# LKS32MC03x register map
Vendor: Linko Ltd.; Series: LKS32MC03x; File version: 1.0
CPU: CM0 r1p0, little endian, MPU, no FPU, 3 interrupt priority bits
Registers are 32-bit, read-write, reset 0x0 unless marked. A register's access mark holds for its fields unless they carry their own. Offsets are from the block's base; [hi:lo] are bit positions; {n}, {i} and the like mark numbered series; 'fields as' and 'values as' point back to an identical list.

## EXTI — EXTI registers
Base 0x40010880
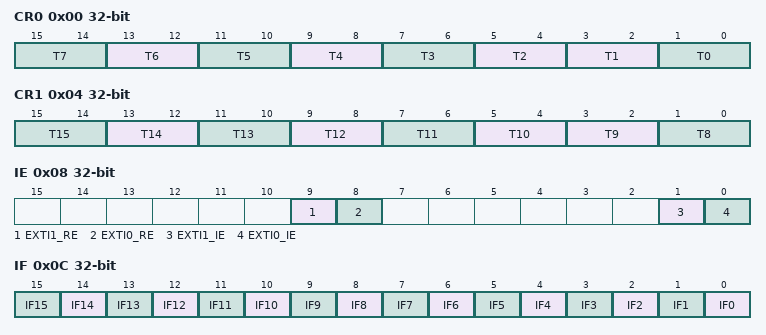
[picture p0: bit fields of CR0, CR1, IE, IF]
0x00 CR0 — GPIO0 external interrupt trigger type
  [all] fields
    0=NONE (No interrupt.); 1=FALLING (Interrupt on falling edge); 2=RISING (Interrupt on rising edge); 3=BOTH (Interrupt on both edges)
  [2n+1:2n] T{n} (n=2..7) — GPIO0[{n+2}] external interrupt trigger type
  [3:2] T1 — GPIO0[2] external interrupt trigger type
  [1:0] T0 — GPIO0[0] external interrupt trigger type
0x04 CR1 — GPIO external interrupt trigger type
  [all] fields
    values as the fields of CR0
  [2n-15:2n-16] T{n} (n=10..15) — GPIO1[{n-6}] external interrupt trigger type
  [3:2] T9 — GPIO0[15] external interrupt trigger type
  [1:0] T8 — GPIO0[14] external interrupt trigger type
0x08 IE — GPIO interrupt enable
  [9] EXTI1_RE — GPIO1 DMA enable
  [8] EXTI0_RE — GPIO0 DMA enable
  [1] EXTI1_IE — GPIO1 interrupt enable
  [0] EXTI0_IE — GPIO0 interrupt enable
0x0C IF — GPIO interrupt flag
  [n] IF{n} (n=0..15) — GPIO0[{n}] interrupt flag
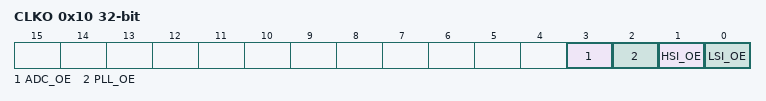
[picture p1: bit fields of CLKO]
0x10 CLKO — GPIO output clock selection
  [3] ADC_OE — ADC output enable
  [2] PLL_OE — PLL output enable
  [1] HSI_OE — HSI output enable
  [0] LSI_OE — LSI output enable

## UART — UART registers
Base 0x40010900
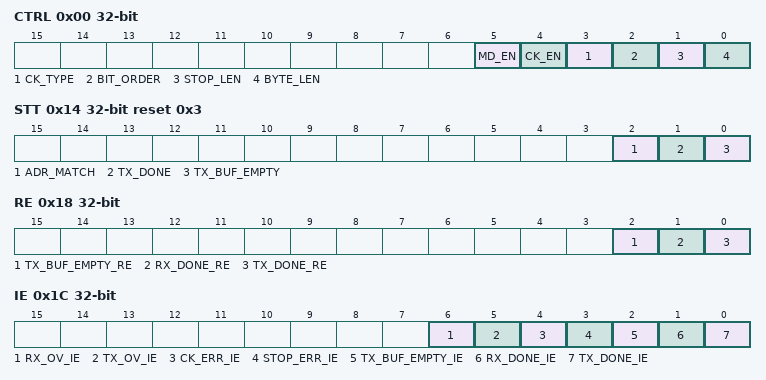
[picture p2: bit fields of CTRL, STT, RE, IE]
0x00 CTRL — UART control
  [5] MD_EN — Multi-drop mode enable
    0=DISABLED (Multi-drop mode disabled); 1=ENABLED (Multi-drop mode enabled)
  [4] CK_EN — Odd-Even Check enable
    0=DISABLED (Odd-Even check disabled); 1=ENABLED (Odd-Even check enabled)
  [3] CK_TYPE — Odd or Even Check
    0=EVEN (Even check); 1=ODD (Odd check)
  [2] BIT_ORDER — LSB or MSB first
    0=LSB; 1=MSB
  [1] STOP_LEN — Stop bit length
    0=1B (1bit stop bit); 1=2B (2bit stop bit)
  [0] BYTE_LEN — Data length
    0=8B (8bit data); 1=9B (9bit data)
0x04 DIVH — UART Baudrate higher byte
  [7:0] DIVH — Baudrate higher byte
0x08 DIVL — UART Baudrate lower byte
  [7:0] DIVL — Baudrate lower byte
0x0C BUFF — UART read/write buffer
  [8:0] DATA — Write by Tx data, read as Rx data
0x10 ADR — UART match address as RS485
  [7:0] ADR — UART address as a slave
0x14 STT ro reset 0x3 — UART status
  [2] ADR_MATCH — Address matched in multi-drop mode
  [1] TX_DONE — Transmission fnished
  [0] TX_BUF_EMPTY — TX Buffer empty
0x18 RE — UART DMA request enable
  [2] TX_BUF_EMPTY_RE — TX Buffer empty DMA request enable
  [1] RX_DONE_RE — Byte received DMA request enable
  [0] TX_DONE_RE — Byte transmission finished DMA request flag
0x1C IE — UART interrupt enable
  [6] RX_OV_IE — RX overflow interrupt enable
  [5] TX_OV_IE — TX overflow interrupt enable
  [4] CK_ERR_IE — Check error interrupt enable
  [3] STOP_ERR_IE — Stop bit error interrupt enable
  [2] TX_BUF_EMPTY_IE — TX Buffer empty interrupt enable
  [1] RX_DONE_IE — Byte received interrupt enable
  [0] TX_DONE_IE — Byte transmission finished interrupt flag
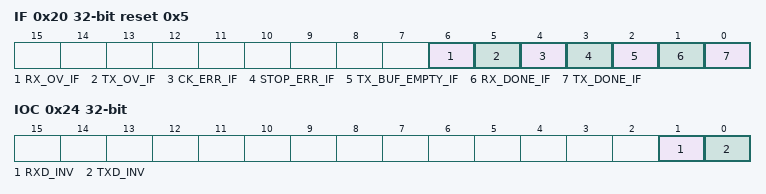
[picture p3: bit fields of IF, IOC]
0x20 IF reset 0x5 — UART interrupt flag
  [6] RX_OV_IF — RX overflow interrupt flag
  [5] TX_OV_IF — TX overflow interrupt flag
  [4] CK_ERR_IF — Check error interrupt flag
  [3] STOP_ERR_IF — Stop bit error interrupt flag
  [2] TX_BUF_EMPTY_IF — TX Buffer empty interrupt flag
  [1] RX_DONE_IF — Byte received interrupt flag
  [0] TX_DONE_IF — Byte transmission finished interrupt flag
0x24 IOC — UART IO Control
  [1] RXD_INV — RXD inverted then input
  [0] TXD_INV — TXD inverted then output

## DMA — DMA registers
Base 0x40010A00
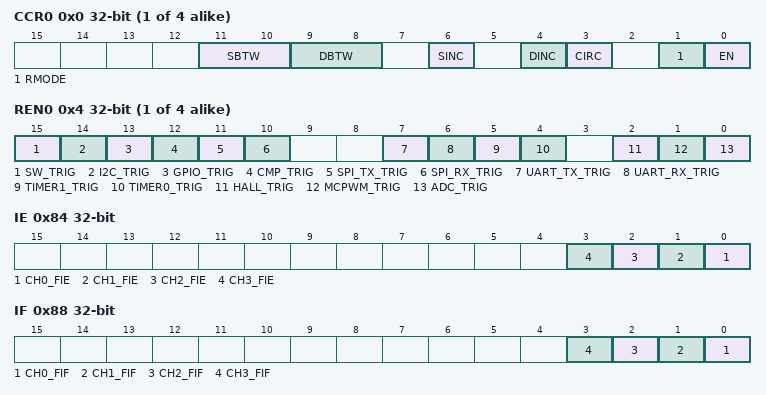
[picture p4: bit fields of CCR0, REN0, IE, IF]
{0x0+0x20*i} CCR{i} (i=0..3) — DMA channel {i} configuration
  [11:10] SBTW — Source data width
    0=BYTE (8bit byte); 1=HALFWORD (16bit halfword); 2=WORD (32bit word)
  [9:8] DBTW — Destination data width
    values as SBTW
  [6] SINC — Source Address Incremental
    0=NINC (Source addr will be increased by SBTW each transfer); 1=INC (Description addr will be increased by DBTW each transfer)
  [4] DINC — Destination Address Incremental
    values as SINC
  [3] CIRC — circular mode
    0=NORMAL (Normal mode); 1=CIRC (Circular mode)
  [1] RMODE — Round mode
    0=SINGLE (Single round, multi-times); 1=MULTI (Multi-round, single time per round)
  [0] EN — channel enable
    0=DISABLED (Channel is disabled); 1=ENABLED (Channel is enabled)
{0x4+0x20*i} REN{i} (i=0..3) — DMA channel {i} request enable
  [15] SW_TRIG — Software trigger enable
  [14] I2C_TRIG — I2C trigger enable
  [13] GPIO_TRIG — GPIO trigger enable
  [12] CMP_TRIG — CMP trigger enable
  [11] SPI_TX_TRIG — SPI_TX trigger enable
  [10] SPI_RX_TRIG — SPI_RX trigger enable
  [7] UART_TX_TRIG — UART_TX trigger enable
  [6] UART_RX_TRIG — UART_RX trigger enable
  [5] TIMER1_TRIG — TIMER1 trigger enable
  [4] TIMER0_TRIG — TIMER0 trigger enable
  [2] HALL_TRIG — HALL trigger enable
  [1] MCPWM_TRIG — MCPWM trigger enable
  [0] ADC_TRIG — ADC trigger enable
{0x8+0x20*i} CTMS{i} (i=0..3) — DMA channel {i} transmission times
  [7:0] TMS — times or rounds
{0xC+0x20*i} SADR{i} (i=0..3) — DMA channel {i} source address
  [31:0] ADDR — Source Address
{0x10+0x20*i} DADR{i} (i=0..3) — DMA channel {i} destination address
  [31:0] ADDR — Destination Address
0x80 CTRL — DMA control
  [0] EN — DMA enable
    0=DISABLED (DMA is disabled); 1=ENABLED (DMA is enabled)
0x84 IE — DMA interrupt enable
  [n] CH{n}_FIE (n=0..3) — channel {n} transmission finish interrupt enable
0x88 IF — DMA interrupt flag
  [n] CH{n}_FIF (n=0..3) — channel {n} transmission finish interrupt flag

## DSP — DSP registers
Base 0x40010B00
0x20 DID — DSP dividend
0x24 DIS — DSP divider
0x28 QUO ro — DSP quotient
0x2C REM ro — DSP remainder
0x30 RAD — DSP radicand
0x34 SQRT 16-bit ro — DSP square root

## IWDG — IWDG registers
Base 0x40010C00
0x00 PSW 16-bit wo — IWDG password
  [15:0] PSW — IWDG access password (excluding CFG)
    0xA6B4=PSW (IWDG access password)
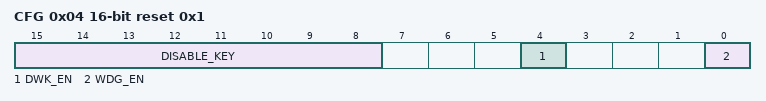
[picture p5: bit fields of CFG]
0x04 CFG 16-bit reset 0x1 — IWDG configuration
  [15:8] DISABLE_KEY wo — IWDG disable key
    60=KEY (IWDG disable key)
  [4] DWK_EN — Deep wakeup enable
    0=DISABLED (IWDG deep wakeup signal is disabled); 1=ENABLED (IWDG deep wakeup signal is enabled)
  [0] WDG_EN — IWDG enable
    0=DISABLED (IWDG is disabled); 1=ENABLED (IWDG is enabled)
0x08 CLR wo — IWDG counter clear
0x0C WTH — IWDG wakeup threshold
  [20:12] WTH — IWDG wakeup theshold
0x10 RTH — IWDG reset threshold
  [20:12] RTH — IWDG bite theshold
0x14 CNT ro — IWDG counter
  [20:0] CNT — IWDG counter value

## AON — AON registers
Base 0x40010C20
0x00 PWR_CFG — Power management configure
  [1] IOWK_FLT — IO wakeup filter enable
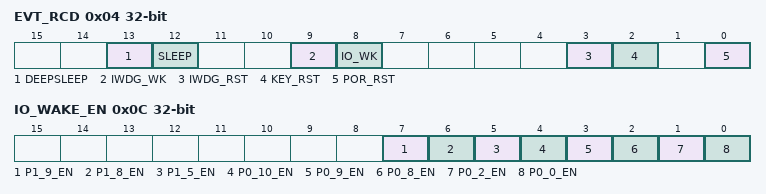
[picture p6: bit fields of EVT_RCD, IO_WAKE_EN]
0x04 EVT_RCD — Event record
  [13] DEEPSLEEP ro — Deep sleep record
  [12] SLEEP ro — Sleep record
  [9] IWDG_WK ro — IWDG wakeup record
  [8] IO_WK ro — IO wakeup record
  [3] IWDG_RST ro — IWDG reset record
  [2] KEY_RST ro — Key reset record
  [0] POR_RST ro — POR record
0x08 IO_WAKE_POL — IO wakeup signal polarity
  [0] WK_POL — Wakeup signal polarity
0x0C IO_WAKE_EN — IO wakeup enable
  [7] P1_9_EN — P1.9 wakeup enable
  [6] P1_8_EN — P1.8 wakeup enable
  [5] P1_5_EN — P1.5 wakeup enable
  [4] P0_10_EN — P0.10 wakeup enable
  [3] P0_9_EN — P0.9 wakeup enable
  [2] P0_8_EN — P0.8 wakeup enable
  [1] P0_2_EN — P0.2 wakeup enable
  [0] P0_0_EN — P0.0 wakeup enable
